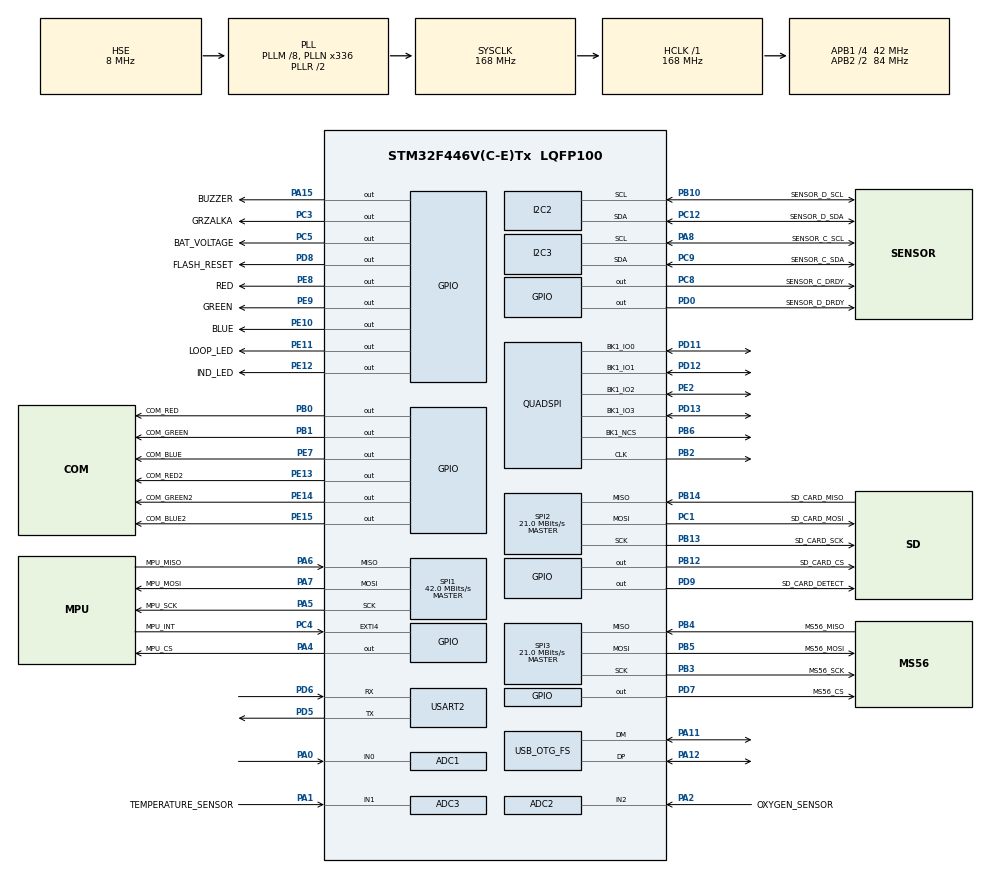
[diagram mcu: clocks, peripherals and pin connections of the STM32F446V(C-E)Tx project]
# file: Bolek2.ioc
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Dma.SPI3_TX.4.PeriphInc=DMA_PINC_DISABLE
PH0-OSC_IN.Signal=RCC_OSC_IN
Dma.SPI1_TX.2.MemInc=DMA_MINC_ENABLE
SPI3.Direction=SPI_DIRECTION_2LINES
SPI3.VirtualType=VM_MASTER
Dma.SPI1_RX.1.FIFOMode=DMA_FIFOMODE_DISABLE
QUADSPI.ClockPrescaler=3
SPI1.VirtualType=VM_MASTER
ADC2.SamplingTime-1\#ChannelRegularConversion=ADC_SAMPLETIME_3CYCLES
SPI2.VirtualType=VM_MASTER
PB10.Mode=I2C
Dma.SPI3_TX.4.Mode=DMA_NORMAL
PC12.Signal=I2C2_SDA
PB14.GPIO_Label=SD_CARD_MISO
PA6.GPIO_Label=MPU_MISO
PB13.Signal=SPI2_SCK
RCC.SYSCLKSource=RCC_SYSCLKSOURCE_PLLRCLK
Dma.SPI3_RX.3.MemDataAlignment=DMA_MDATAALIGN_BYTE
SPI1.Direction=SPI_DIRECTION_2LINES
PE2.Mode=Single Bank 1
RCC.APB2TimFreq_Value=168000000
PB6.Signal=QUADSPI_BK1_NCS
PB6.Mode=Single Bank 1
SPI1.CalculateBaudRate=42.0 MBits/s
PC3.Signal=GPIO_Output
PD0.Signal=GPIO_Output
PD8.Signal=GPIO_Output
QUADSPI.FlashSize=31
Dma.SPI3_TX.4.Instance=DMA1_Stream5
Dma.SPI3_RX.3.Mode=DMA_NORMAL
NVIC.TIM8_TRG_COM_TIM14_IRQn=true\:0\:0\:false\:false\:true\:true\:true
USB_OTG_FS.phy_itface=HCD_PHY_EMBEDDED
PB2.Signal=QUADSPI_CLK
PB3.Mode=Full_Duplex_Master
Dma.SPI1_RX.1.Priority=DMA_PRIORITY_LOW
PB12.GPIO_Label=SD_CARD_CS
PC4.GPIO_Label=MPU_INT
PE9.Signal=GPIO_Output
PB14.Mode=Full_Duplex_Master
PB1.GPIO_Label=COM_GREEN
ADC3.ContinuousConvMode=ENABLE
PC9.Mode=I2C
SPI2.CalculateBaudRate=21.0 MBits/s
PE2.Signal=QUADSPI_BK1_IO2
PA8.Signal=I2C3_SCL
PE10.Signal=GPIO_Output
ADC1.SamplingTime-0\#ChannelRegularConversion=ADC_SAMPLETIME_3CYCLES
Mcu.Package=LQFP100
PB1.Signal=GPIO_Output
NVIC.TimeBase=TIM8_UP_TIM13_IRQn
SPI2.Mode=SPI_MODE_MASTER
SPI3.Mode=SPI_MODE_MASTER
PD12.Signal=QUADSPI_BK1_IO1
ADC2.Channel-1\#ChannelRegularConversion=ADC_CHANNEL_2
NVIC.TimeBaseIP=TIM13
PE12.GPIO_Label=IND_LED
RCC.APB2CLKDivider=RCC_HCLK_DIV2
RCC.APB1TimFreq_Value=84000000
PB13.Mode=Full_Duplex_Master
VP_TIM14_VS_ClockSourceINT.Mode=Enable_Timer
Dma.SPI1_TX.2.Priority=DMA_PRIORITY_LOW
PE10.GPIO_Label=BLUE
Dma.QUADSPI.0.PeriphDataAlignment=DMA_PDATAALIGN_BYTE
Dma.SPI1_RX.1.MemInc=DMA_MINC_ENABLE
PA4.GPIO_Label=MPU_CS
Dma.SPI1_TX.2.PeriphInc=DMA_PINC_DISABLE
PA5.Mode=Full_Duplex_Master
Dma.SPI1_RX.1.Instance=DMA2_Stream0
NVIC.EXTI4_IRQn=true\:5\:0\:true\:false\:true\:true\:true
NVIC.QUADSPI_IRQn=true\:5\:0\:true\:false\:true\:true\:true
ADC1.Rank-0\#ChannelRegularConversion=1
PD9.GPIO_Label=SD_CARD_DETECT
Dma.SPI1_RX.1.MemDataAlignment=DMA_MDATAALIGN_BYTE
PD7.Signal=GPIO_Output
RCC.APB1CLKDivider=RCC_HCLK_DIV4
PD6.Mode=Asynchronous
PA0-WKUP.Signal=ADCx_IN0
PA8.GPIO_Label=SENSOR_C_SCL
PE8.GPIO_Label=RED
NVIC.I2C2_ER_IRQn=true\:5\:0\:true\:false\:true\:true\:true
Dma.SPI3_RX.3.PeriphInc=DMA_PINC_DISABLE
PE9.GPIO_Label=GREEN
PB10.Signal=I2C2_SCL
PB14.Signal=SPI2_MISO
PA5.Signal=SPI1_SCK
PC12.Mode=I2C
Dma.SPI3_TX.4.MemDataAlignment=DMA_MDATAALIGN_BYTE
NVIC.SPI1_IRQn=true\:5\:0\:true\:false\:true\:true\:true
PE14.Signal=GPIO_Output
PE15.Signal=GPIO_Output
PB4.GPIO_Label=MS56_MISO
PE8.Signal=GPIO_Output
SPI1.Mode=SPI_MODE_MASTER
PA1.GPIO_Label=TEMPERATURE_SENSOR
PA13.Mode=Serial_Wire
ADC3.Channel-1\#ChannelRegularConversion=ADC_CHANNEL_1
Dma.SPI3_TX.4.PeriphDataAlignment=DMA_PDATAALIGN_BYTE
ADC3.Rank-1\#ChannelRegularConversion=1
PA4.Signal=GPIO_Output
PB5.Signal=SPI3_MOSI
ADC1.master=1
PE13.GPIO_Label=COM_RED2
PD12.Mode=Single Bank 1
PA5.GPIO_Label=MPU_SCK
ADC2.NbrOfConversionFlag=1
PD11.Signal=QUADSPI_BK1_IO0
PC12.GPIO_Label=SENSOR_D_SDA
PA11.Signal=USB_OTG_FS_DM
ProjectManager.HeapSize=0x200
Dma.SPI3_RX.3.PeriphDataAlignment=DMA_PDATAALIGN_BYTE
NVIC.TIM8_UP_TIM13_IRQn=true\:0\:0\:false\:false\:true\:false\:true
NVIC.PriorityGroup=NVIC_PRIORITYGROUP_4
NVIC.I2C3_ER_IRQn=true\:5\:0\:true\:false\:true\:true\:true
PC3.GPIO_Label=GRZALKA
PA8.Mode=I2C
Dma.SPI3_TX.4.Direction=DMA_MEMORY_TO_PERIPH
PB0.Signal=GPIO_Output
Dma.SPI3_TX.4.Priority=DMA_PRIORITY_LOW
PC1.Signal=SPI2_MOSI
PC1.Mode=Full_Duplex_Master
Mcu.Family=STM32F4
Dma.SPI3_RX.3.Direction=DMA_PERIPH_TO_MEMORY
Dma.SPI3_TX.4.MemInc=DMA_MINC_ENABLE
PA6.Mode=Full_Duplex_Master
RCC.CortexFreq_Value=168000000
Dma.SPI1_RX.1.Mode=DMA_NORMAL
PE11.GPIO_Label=LOOP_LED
SH.ADCx_IN2.0=ADC2_IN2,IN2
Dma.QUADSPI.0.Instance=DMA2_Stream7
PD0.GPIO_Label=SENSOR_D_DRDY
PA11.Mode=Host_Only
PB0.GPIO_Label=COM_RED
Dma.QUADSPI.0.MemDataAlignment=DMA_MDATAALIGN_BYTE
PB13.GPIO_Label=SD_CARD_SCK
ProjectManager.StackSize=0x400
Dma.QUADSPI.0.FIFOMode=DMA_FIFOMODE_DISABLE
PD13.Signal=QUADSPI_BK1_IO3
NVIC.ADC_IRQn=true\:5\:0\:true\:false\:true\:true\:true
PA15.GPIO_Label=BUZZER
PA12.Signal=USB_OTG_FS_DP
Dma.SPI1_RX.1.PeriphInc=DMA_PINC_DISABLE
RCC.HCLKFreq_Value=168000000
NVIC.DMA2_Stream0_IRQn=true\:5\:0\:true\:false\:true\:false\:true
Dma.SPI1_TX.2.Mode=DMA_NORMAL
RCC.AHBFreq_Value=168000000
PH0-OSC_IN.Mode=HSE-External-Oscillator
PD5.Mode=Asynchronous
ADC3.SamplingTime-1\#ChannelRegularConversion=ADC_SAMPLETIME_480CYCLES
ADC1.Channel-0\#ChannelRegularConversion=ADC_CHANNEL_0
RCC.HSE_VALUE=8000000
Dma.SPI3_RX.3.Priority=DMA_PRIORITY_LOW
NVIC.I2C3_EV_IRQn=true\:5\:0\:true\:false\:true\:true\:true
PB4.Mode=Full_Duplex_Master
PE13.Signal=GPIO_Output
PA14.Mode=Serial_Wire
PB5.Mode=Full_Duplex_Master
NVIC.SPI2_IRQn=true\:5\:0\:true\:false\:true\:true\:true
SH.ADCx_IN0.0=ADC1_IN0,IN0
Dma.SPI1_RX.1.Direction=DMA_PERIPH_TO_MEMORY
PD7.GPIO_Label=MS56_CS
PH1-OSC_OUT.Mode=HSE-External-Oscillator
Dma.SPI1_TX.2.MemDataAlignment=DMA_MDATAALIGN_BYTE
PA6.Signal=SPI1_MISO
NVIC.DMA2_Stream7_IRQn=true\:5\:0\:true\:false\:true\:false\:true
Dma.QUADSPI.0.Direction=DMA_PERIPH_TO_MEMORY
Dma.QUADSPI.0.Priority=DMA_PRIORITY_LOW
USART2.VirtualMode=VM_ASYNC
PA2.GPIO_Label=OXYGEN_SENSOR
USB_OTG_FS.VirtualMode=Host_Only
PA15.Signal=GPIO_Output
NVIC.SPI3_IRQn=true\:5\:0\:true\:false\:true\:true\:true
ADC3.ClockPrescaler=ADC_CLOCK_SYNC_PCLK_DIV8
PB5.GPIO_Label=MS56_MOSI
Dma.Request2=SPI1_TX
Dma.Request1=SPI1_RX
Dma.Request4=SPI3_TX
Dma.Request3=SPI3_RX
NVIC.DMA1_Stream0_IRQn=true\:5\:0\:true\:false\:true\:false\:true
SPI2.Direction=SPI_DIRECTION_2LINES
PC5.Signal=GPIO_Output
PE7.Signal=GPIO_Output
PD6.Signal=USART2_RX
Dma.Request0=QUADSPI
PB4.Signal=SPI3_MISO
PB3.GPIO_Label=MS56_SCK
ADC2.ClockPrescaler=ADC_CLOCK_SYNC_PCLK_DIV8
PA7.Mode=Full_Duplex_Master
Dma.SPI1_TX.2.Direction=DMA_MEMORY_TO_PERIPH
PC9.GPIO_Label=SENSOR_C_SDA
PC8.Signal=GPIO_Output
Dma.QUADSPI.0.MemInc=DMA_MINC_ENABLE
PC4.Signal=GPXTI4
Dma.QUADSPI.0.PeriphInc=DMA_PINC_DISABLE
PE14.GPIO_Label=COM_GREEN2
PD9.Signal=GPIO_Output
PD5.Signal=USART2_TX
NVIC.USART2_IRQn=true\:5\:0\:true\:false\:true\:true\:true
PD8.GPIO_Label=FLASH_RESET
PC8.GPIO_Label=SENSOR_C_DRDY
PA13.Signal=SYS_JTMS-SWDIO
Dma.SPI1_TX.2.Instance=DMA2_Stream3
Dma.SPI3_RX.3.MemInc=DMA_MINC_ENABLE
PE15.GPIO_Label=COM_BLUE2
ProjectManager.TargetToolchain=SW4STM32
PB10.GPIO_Label=SENSOR_D_SCL
NVIC.DMA1_Stream5_IRQn=true\:5\:0\:true\:false\:true\:false\:true
SH.S_TIM4_CH3.0=TIM4_CH3
PD13.Mode=Single Bank 1
Dma.SPI1_TX.2.FIFOMode=DMA_FIFOMODE_DISABLE
Dma.QUADSPI.0.Mode=DMA_NORMAL
RCC.USBFreq_Value=48000000
Dma.SPI1_TX.2.PeriphDataAlignment=DMA_PDATAALIGN_BYTE
Dma.SPI3_TX.4.FIFOMode=DMA_FIFOMODE_DISABLE
NVIC.DMA2_Stream3_IRQn=true\:5\:0\:true\:false\:true\:false\:true
PE11.Signal=GPIO_Output
PA1.Signal=SharedAnalog_PA1
board=custom
RCC.VCOOutputFreq_Value=336000000
RCC.APB2Freq_Value=84000000
SPI3.CalculateBaudRate=21.0 MBits/s
VP_SYS_VS_tim13.Mode=TIM13
PC1.GPIO_Label=SD_CARD_MOSI
Dma.SPI3_RX.3.FIFOMode=DMA_FIFOMODE_DISABLE
PH1-OSC_OUT.Signal=RCC_OSC_OUT
Mcu.Name=STM32F446V(C-E)Tx
PE7.GPIO_Label=COM_BLUE
PE12.Signal=GPIO_Output
PA2.Signal=ADCx_IN2
Dma.SPI1_RX.1.PeriphDataAlignment=DMA_PDATAALIGN_BYTE
PB3.Signal=SPI3_SCK
RCC.SYSCLKFreq_VALUE=168000000
PA7.GPIO_Label=MPU_MOSI
PA12.Mode=Host_Only
PC5.GPIO_Label=BAT_VOLTAGE
PB2.Mode=Single Bank 1
PA14.Signal=SYS_JTCK-SWCLK
PD11.Mode=Single Bank 1
NVIC.I2C2_EV_IRQn=true\:5\:0\:true\:false\:true\:true\:true
SH.SharedAnalog_PA1.1=ADC3_IN1,IN1
RCC.PLLQ=7
SH.SharedAnalog_PA1.0=GPIO_Analog
ADC1.NbrOfConversionFlag=1
RCC.PLLM=8
RCC.PLLN=336
ADC2.Rank-1\#ChannelRegularConversion=1
PB8.Signal=S_TIM4_CH3
Dma.SPI3_RX.3.Instance=DMA1_Stream0
PC9.Signal=I2C3_SDA
RCC.APB1Freq_Value=42000000
ADC3.NbrOfConversionFlag=1
ADC1.ClockPrescaler=ADC_CLOCK_SYNC_PCLK_DIV8
PB12.Signal=GPIO_Output
PA7.Signal=SPI1_MOSI

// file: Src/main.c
/* USER CODE BEGIN Header */
/**
  ******************************************************************************
  * @file           : main.c
  * @brief          : Main program body
  ******************************************************************************
  * @attention
  *
  * <h2><center>&copy; Copyright (c) 2021 STMicroelectronics.
  * All rights reserved.</center></h2>
  *
  * This software component is licensed by ST under BSD 3-Clause license,
  * the "License"; You may not use this file except in compliance with the
  * License. You may obtain a copy of the License at:
  *                        opensource.org/licenses/BSD-3-Clause
  *
  ******************************************************************************
  */
/* USER CODE END Header */

#include "main.h"
#include "adc.h"
#include "dma.h"
#include "i2c.h"
#include "quadspi.h"
#include "spi.h"
#include "tim.h"
#include "usart.h"
#include "usb_otg.h"
#include "gpio.h"

/* USER CODE BEGIN Includes */
#include "SS_platform.h"
#include "SS_common.h"
/* USER CODE END Includes */

void SystemClock_Config(void);

int main(void)
{

  /* MCU Configuration--------------------------------------------------------*/

  /* Reset of all peripherals, Initializes the Flash interface and the Systick. */
  HAL_Init();

  /* Configure the system clock */
  SystemClock_Config();

  /* Initialize all configured peripherals */
  MX_GPIO_Init();
  MX_DMA_Init();
  MX_ADC1_Init();
  MX_ADC2_Init();
  MX_I2C2_Init();
  MX_I2C3_Init();
  MX_QUADSPI_Init();
  MX_SPI1_Init();
  MX_SPI2_Init();
  MX_SPI3_Init();
  MX_TIM14_Init();
  MX_USART2_UART_Init();
  MX_USB_OTG_FS_HCD_Init();
  MX_ADC3_Init();
  /* USER CODE BEGIN 2 */
    SS_platform_init();
    SS_init();
  /* USER CODE END 2 */

  /* Infinite loop */
  while (1)
  {

  }
}

void SystemClock_Config(void)
{
  RCC_OscInitTypeDef RCC_OscInitStruct = {0};
  RCC_ClkInitTypeDef RCC_ClkInitStruct = {0};
  RCC_PeriphCLKInitTypeDef PeriphClkInitStruct = {0};

  /** Configure the main internal regulator output voltage
  */
  __HAL_RCC_PWR_CLK_ENABLE();
  __HAL_PWR_VOLTAGESCALING_CONFIG(PWR_REGULATOR_VOLTAGE_SCALE1);
  /** Initializes the CPU, AHB and APB busses clocks
  */
  RCC_OscInitStruct.OscillatorType = RCC_OSCILLATORTYPE_HSE;
  RCC_OscInitStruct.HSEState = RCC_HSE_ON;
  RCC_OscInitStruct.PLL.PLLState = RCC_PLL_ON;
  RCC_OscInitStruct.PLL.PLLSource = RCC_PLLSOURCE_HSE;
  RCC_OscInitStruct.PLL.PLLM = 8;
  RCC_OscInitStruct.PLL.PLLN = 336;
  RCC_OscInitStruct.PLL.PLLP = RCC_PLLP_DIV2;
  RCC_OscInitStruct.PLL.PLLQ = 7;
  RCC_OscInitStruct.PLL.PLLR = 2;
  if (HAL_RCC_OscConfig(&RCC_OscInitStruct) != HAL_OK)
  {
    Error_Handler();
  }
  /** Initializes the CPU, AHB and APB busses clocks
  */
  RCC_ClkInitStruct.ClockType = RCC_CLOCKTYPE_HCLK|RCC_CLOCKTYPE_SYSCLK
                              |RCC_CLOCKTYPE_PCLK1|RCC_CLOCKTYPE_PCLK2;
  RCC_ClkInitStruct.SYSCLKSource = RCC_SYSCLKSOURCE_PLLRCLK;
  RCC_ClkInitStruct.AHBCLKDivider = RCC_SYSCLK_DIV1;
  RCC_ClkInitStruct.APB1CLKDivider = RCC_HCLK_DIV4;
  RCC_ClkInitStruct.APB2CLKDivider = RCC_HCLK_DIV2;

  if (HAL_RCC_ClockConfig(&RCC_ClkInitStruct, FLASH_LATENCY_5) != HAL_OK)
  {
    Error_Handler();
  }
  PeriphClkInitStruct.PeriphClockSelection = RCC_PERIPHCLK_CLK48;
  PeriphClkInitStruct.Clk48ClockSelection = RCC_CLK48CLKSOURCE_PLLQ;
  if (HAL_RCCEx_PeriphCLKConfig(&PeriphClkInitStruct) != HAL_OK)
  {
    Error_Handler();
  }
}

 /**
  * @brief  Period elapsed callback in non blocking mode
  * @note   This function is called  when TIM13 interrupt took place, inside
  * HAL_TIM_IRQHandler(). It makes a direct call to HAL_IncTick() to increment
  * a global variable "uwTick" used as application time base.
  * @param  htim : TIM handle
  * @retval None
  */
void HAL_TIM_PeriodElapsedCallback(TIM_HandleTypeDef *htim)
{
  if (htim->Instance == TIM13) {
    HAL_IncTick();
  }
}

void Error_Handler(void)
{
}

/************************ (C) COPYRIGHT STMicroelectronics *****END OF FILE****/
